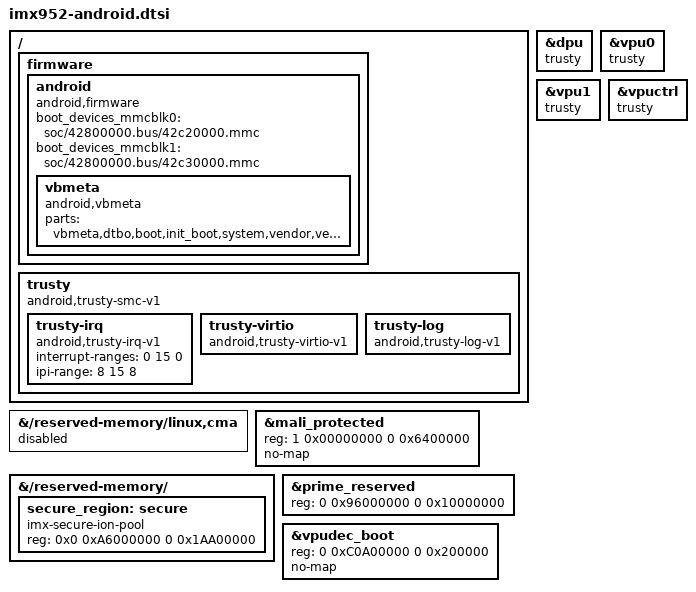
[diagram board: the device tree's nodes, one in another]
// SPDX-License-Identifier: (GPL-2.0+ OR MIT)
/*
 * Copyright 2023 NXP
 */

/ {
	firmware {
		android {
			compatible = "android,firmware";
			/* sd card node which used if androidboot.boot_device_root=mmcblk0 */
			boot_devices_mmcblk0 = "soc/42800000.bus/42c20000.mmc";
			/* emmc node which used if androidboot.boot_device_root=mmcblk1 */
			boot_devices_mmcblk1 = "soc/42800000.bus/42c30000.mmc";
			vbmeta {
				/*we need use FirstStageMountVBootV2 if we enable avb*/
				compatible = "android,vbmeta";
				/*parts means the partition witch can be mount in first stage*/
				parts = "vbmeta,dtbo,boot,init_boot,system,vendor,vendor_dlkm,product";
			};
		};
	};

	trusty {
		compatible = "android,trusty-smc-v1";
		ranges;
		#address-cells = <2>;
		#size-cells = <2>;
		trusty-irq {
			compatible = "android,trusty-irq-v1";
			interrupt-ranges = < 0 15 0>;
			ipi-range = <8 15 8>;
		};
		trusty-virtio {
			compatible = "android,trusty-virtio-v1";
		};
		trusty-log {
			compatible = "android,trusty-log-v1";
		};
	};
};

&{/reserved-memory/linux,cma} {
       status = "disabled";
};

&mali_protected {
	reg = <1 0x00000000 0 0x6400000>;
	no-map;
};

&dpu {
        trusty;
};

&{/reserved-memory/} {
	secure_region: secure {
		compatible = "imx-secure-ion-pool";
		reg = <0x0 0xA6000000 0 0x1AA00000>;
	};
};

&prime_reserved {
	reg = <0 0x96000000 0 0x10000000>;
};

&vpu0 {
	trusty;
};

&vpu1 {
	status = "okay";
	trusty;
};

&vpuctrl {
	trusty;
};

&vpudec_boot {
	reg = <0 0xC0A00000 0 0x200000>;
	no-map;
};
